# SA3_SS_SA_UL_0_SA_UL_RNG_40910000h register map
Vendor: Texas Instruments
Peripheral module from a debugger description file (folder AM275x).
Registers are 32-bit, write-only, reset 0x0 unless marked. A register's access mark holds for its fields unless they carry their own. Offsets are as the file gives them; lines under a group give offsets from that group; [hi:lo] are bit positions; {n}, {i} and the like mark numbered series; 'fields as' and 'values as' point back to an identical list; <NAME> marks a mode.

## sa_ul_rng
{0x0+4i} SA_UL_RNG_TRNG_INPUT_{i} (i=0..3)
  [31:0] TRNG_INPUT_{i}
{0x0+4i} SA_UL_RNG_TRNG_OUTPUT_{i} ro (i=0..3)
  [31:0] TRNG_OUTPUT_{i}
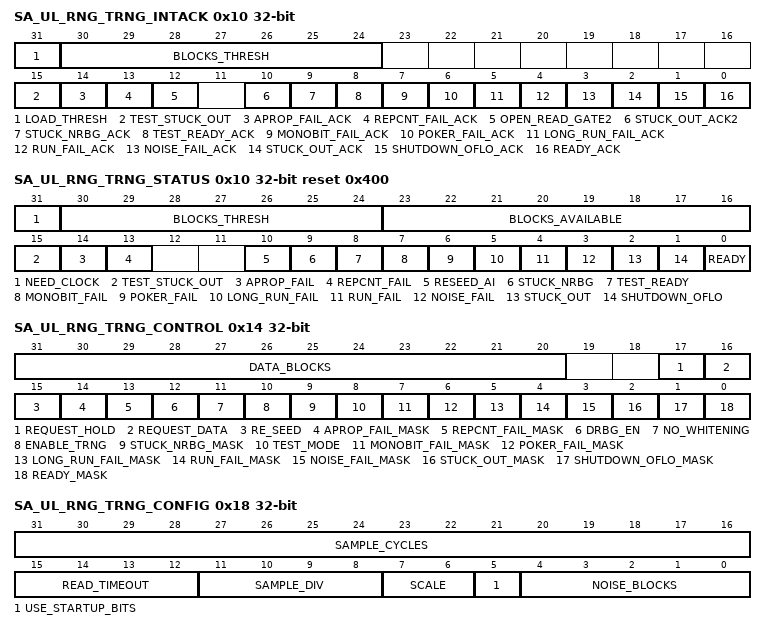
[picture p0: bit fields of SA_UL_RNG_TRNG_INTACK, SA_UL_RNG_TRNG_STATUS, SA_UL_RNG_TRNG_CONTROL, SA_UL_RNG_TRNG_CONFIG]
0x10 SA_UL_RNG_TRNG_INTACK
  [31] LOAD_THRESH, [30:24] BLOCKS_THRESH, [15] TEST_STUCK_OUT, [14] APROP_FAIL_ACK, [13] REPCNT_FAIL_ACK, [12] OPEN_READ_GATE2, [10] STUCK_OUT_ACK2, [9] STUCK_NRBG_ACK, [8] TEST_READY_ACK, [7] MONOBIT_FAIL_ACK, [6] POKER_FAIL_ACK, [5] LONG_RUN_FAIL_ACK, [4] RUN_FAIL_ACK, [3] NOISE_FAIL_ACK, [2] STUCK_OUT_ACK, [1] SHUTDOWN_OFLO_ACK, [0] READY_ACK
0x10 SA_UL_RNG_TRNG_INTACK_SECURE_MODE
  [14:0] READY
0x10 SA_UL_RNG_TRNG_STATUS ro reset 0x400
  [31] NEED_CLOCK, [30:24] BLOCKS_THRESH, [23:16] BLOCKS_AVAILABLE, [15] TEST_STUCK_OUT, [14] APROP_FAIL, [13] REPCNT_FAIL, [10] RESEED_AI, [9] STUCK_NRBG, [8] TEST_READY, [7] MONOBIT_FAIL, [6] POKER_FAIL, [5] LONG_RUN_FAIL, [4] RUN_FAIL, [3] NOISE_FAIL, [2] STUCK_OUT, [1] SHUTDOWN_OFLO, [0] READY
0x14 SA_UL_RNG_TRNG_CONTROL access per field
  [31:20] DATA_BLOCKS rw, [17] REQUEST_HOLD rw, [16] REQUEST_DATA wo, [15] RE_SEED rw, [14] APROP_FAIL_MASK rw, [13] REPCNT_FAIL_MASK rw, [12] DRBG_EN rw, [11] NO_WHITENING rw, [10] ENABLE_TRNG rw, [9] STUCK_NRBG_MASK rw, [8] TEST_MODE rw, [7] MONOBIT_FAIL_MASK rw, [6] POKER_FAIL_MASK rw, [5] LONG_RUN_FAIL_MASK rw, [4] RUN_FAIL_MASK rw, [3] NOISE_FAIL_MASK rw, [2] STUCK_OUT_MASK rw, [1] SHUTDOWN_OFLO_MASK rw, [0] READY_MASK rw
0x18 SA_UL_RNG_TRNG_CONFIG rw
  [31:16] SAMPLE_CYCLES, [15:12] READ_TIMEOUT, [11:8] SAMPLE_DIV, [7:6] SCALE, [5] USE_STARTUP_BITS, [4:0] NOISE_BLOCKS
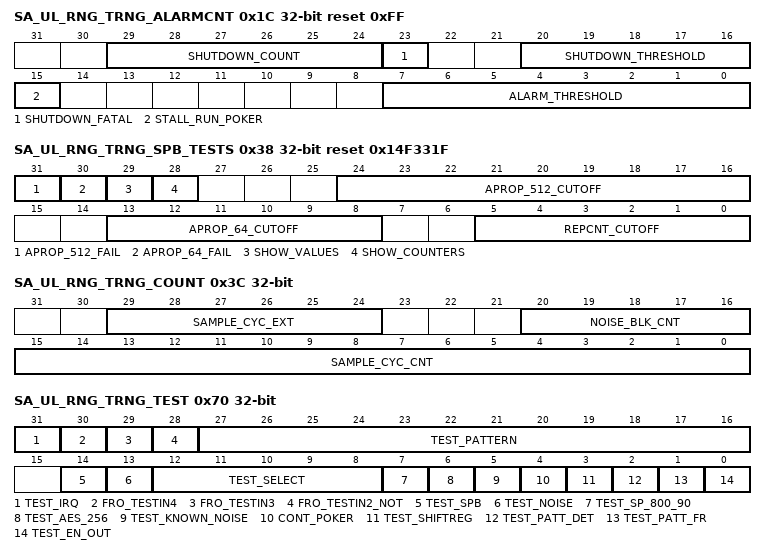
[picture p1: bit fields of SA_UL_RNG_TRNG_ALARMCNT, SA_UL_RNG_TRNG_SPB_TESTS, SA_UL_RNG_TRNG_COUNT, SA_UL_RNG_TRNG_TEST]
0x1C SA_UL_RNG_TRNG_ALARMCNT access per field reset 0xFF
  [29:24] SHUTDOWN_COUNT ro, [23] SHUTDOWN_FATAL rw, [20:16] SHUTDOWN_THRESHOLD rw, [15] STALL_RUN_POKER rw, [7:0] ALARM_THRESHOLD rw
0x20 SA_UL_RNG_TRNG_FROENABLE rw reset 0xFF
  [7:0] TRNG_FROENABLE
0x24 SA_UL_RNG_TRNG_FRODETUNE rw
  [7:0] TRNG_FRODETUNE
0x28 SA_UL_RNG_TRNG_ALARMMASK rw
  [7:0] TRNG_ALARMMASK
0x2C SA_UL_RNG_TRNG_ALARMSTOP rw
  [7:0] TRNG_ALARMSTOP
0x30 SA_UL_RNG_TRNG_RAW_L rw
  [31:0] TRNG_RAW_L
0x34 SA_UL_RNG_TRNG_RAW_H rw
  [31:0] TRNG_RAW_H
0x38 SA_UL_RNG_TRNG_SPB_TESTS access per field reset 0x14F331F
  [31] APROP_512_FAIL rw, [30] APROP_64_FAIL rw, [29] SHOW_VALUES rw, [28] SHOW_COUNTERS rw, [24:16] APROP_512_CUTOFF rw, [13:8] APROP_64_CUTOFF rw, [5:0] REPCNT_CUTOFF rw
0x3C SA_UL_RNG_TRNG_COUNT ro
  [29:24] SAMPLE_CYC_EXT, [20:16] NOISE_BLK_CNT, [15:0] SAMPLE_CYC_CNT
{0x40+4i} SA_UL_RNG_TRNG_PS_AI_{i} (i=0..11)
  [31:0] VECTOR
0x70 SA_UL_RNG_TRNG_TEST access per field
  [31] TEST_IRQ rw, [30] FRO_TESTIN4 rw, [29] FRO_TESTIN3 rw, [28] FRO_TESTIN2_NOT rw, [27:16] TEST_PATTERN rw, [14] TEST_SPB rw, [13] TEST_NOISE rw, [12:8] TEST_SELECT rw, [7] TEST_SP_800_90 rw, [6] TEST_AES_256 rw, [5] TEST_KNOWN_NOISE rw, [4] CONT_POKER rw, [3] TEST_SHIFTREG rw, [2] TEST_PATT_DET rw, [1] TEST_PATT_FR rw, [0] TEST_EN_OUT rw
0x74 SA_UL_RNG_TRNG_BLOCKCNT access per field
  [31:4] BLOCK_COUNT rw
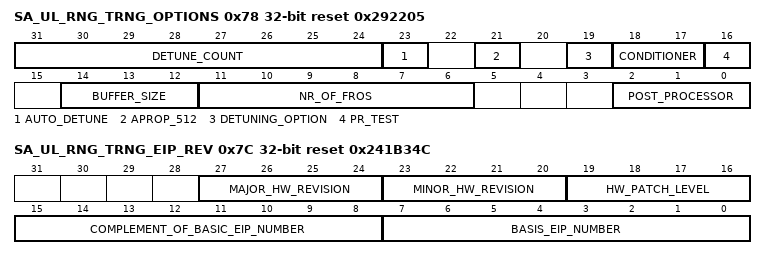
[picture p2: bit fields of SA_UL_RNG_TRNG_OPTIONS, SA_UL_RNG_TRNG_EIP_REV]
0x78 SA_UL_RNG_TRNG_OPTIONS access per field reset 0x292205
  [31:24] DETUNE_COUNT rw, [23] AUTO_DETUNE rw, [21] APROP_512 ro, [19] DETUNING_OPTION ro, [18:17] CONDITIONER ro, [16] PR_TEST ro, [14:12] BUFFER_SIZE ro, [11:6] NR_OF_FROS ro, [2:0] POST_PROCESSOR ro
0x7C SA_UL_RNG_TRNG_EIP_REV ro reset 0x241B34C
  [27:24] MAJOR_HW_REVISION, [23:20] MINOR_HW_REVISION, [19:16] HW_PATCH_LEVEL, [15:8] COMPLEMENT_OF_BASIC_EIP_NUMBER, [7:0] BASIS_EIP_NUMBER
